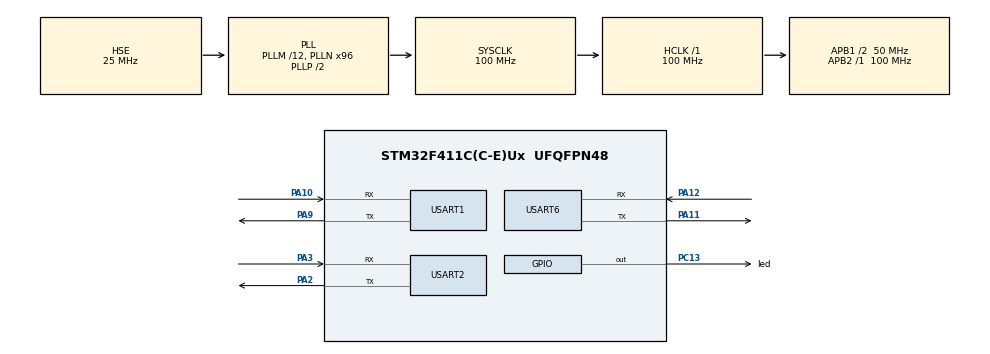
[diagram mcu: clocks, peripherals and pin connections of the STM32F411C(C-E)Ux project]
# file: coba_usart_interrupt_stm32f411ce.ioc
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Dma.Request0=USART2_TX
Dma.USART2_TX.0.Direction=DMA_MEMORY_TO_PERIPH
Dma.USART2_TX.0.FIFOMode=DMA_FIFOMODE_DISABLE
Dma.USART2_TX.0.Instance=DMA1_Stream6
Dma.USART2_TX.0.MemDataAlignment=DMA_MDATAALIGN_BYTE
Dma.USART2_TX.0.MemInc=DMA_MINC_ENABLE
Dma.USART2_TX.0.Mode=DMA_NORMAL
Dma.USART2_TX.0.PeriphDataAlignment=DMA_PDATAALIGN_BYTE
Dma.USART2_TX.0.PeriphInc=DMA_PINC_DISABLE
Dma.USART2_TX.0.Priority=DMA_PRIORITY_LOW
Mcu.Family=STM32F4
Mcu.Name=STM32F411C(C-E)Ux
Mcu.Package=UFQFPN48
NVIC.DMA1_Stream6_IRQn=true\:0\:0\:false\:false\:true\:false\:true
NVIC.PriorityGroup=NVIC_PRIORITYGROUP_4
NVIC.TIM2_IRQn=true\:0\:0\:false\:false\:true\:true\:true
NVIC.USART1_IRQn=true\:0\:0\:false\:false\:true\:true\:true
NVIC.USART2_IRQn=true\:0\:0\:false\:false\:true\:true\:true
NVIC.USART6_IRQn=true\:0\:0\:false\:false\:true\:true\:true
PA10.Mode=Asynchronous
PA10.Signal=USART1_RX
PA11.Mode=Asynchronous
PA11.Signal=USART6_TX
PA12.Mode=Asynchronous
PA12.Signal=USART6_RX
PA13.Mode=Serial_Wire
PA13.Signal=SYS_JTMS-SWDIO
PA14.Mode=Serial_Wire
PA14.Signal=SYS_JTCK-SWCLK
PA2.Mode=Asynchronous
PA2.Signal=USART2_TX
PA3.Mode=Asynchronous
PA3.Signal=USART2_RX
PA9.Mode=Asynchronous
PA9.Signal=USART1_TX
PC13-ANTI_TAMP.GPIO_Label=led
PC13-ANTI_TAMP.Signal=GPIO_Output
PH0\ -\ OSC_IN.Mode=HSE-External-Oscillator
PH0\ -\ OSC_IN.Signal=RCC_OSC_IN
PH1\ -\ OSC_OUT.Mode=HSE-External-Oscillator
PH1\ -\ OSC_OUT.Signal=RCC_OSC_OUT
ProjectManager.HeapSize=0x200
ProjectManager.StackSize=0x400
ProjectManager.TargetToolchain=STM32CubeIDE
RCC.48MHZClocksFreq_Value=50000000
RCC.AHBFreq_Value=100000000
RCC.APB1CLKDivider=RCC_HCLK_DIV2
RCC.APB1Freq_Value=50000000
RCC.APB1TimFreq_Value=100000000
RCC.APB2Freq_Value=100000000
RCC.APB2TimFreq_Value=100000000
RCC.CortexFreq_Value=100000000
RCC.HCLKFreq_Value=100000000
RCC.HSE_VALUE=25000000
RCC.HSI_VALUE=16000000
RCC.LSE_VALUE=32768
RCC.PLLM=12
RCC.PLLN=96
RCC.PLLSourceVirtual=RCC_PLLSOURCE_HSE
RCC.SYSCLKFreq_VALUE=100000000
RCC.SYSCLKSource=RCC_SYSCLKSOURCE_PLLCLK
RCC.VCOOutputFreq_Value=200000000
TIM2.AutoReloadPreload=TIM_AUTORELOAD_PRELOAD_ENABLE
TIM2.Period=65535
TIM2.Prescaler=65535
USART1.VirtualMode=VM_ASYNC
USART2.VirtualMode=VM_ASYNC
USART6.VirtualMode=VM_ASYNC
VP_TIM2_VS_ClockSourceINT.Mode=Internal
board=custom

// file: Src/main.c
/* USER CODE BEGIN Header */
/**
  ******************************************************************************
  * @file           : main.c
  * @brief          : Main program body
  ******************************************************************************
  * @attention
  *
  * Copyright (c) 2022 STMicroelectronics.
  * All rights reserved.
  *
  * This software is licensed under terms that can be found in the LICENSE file
  * in the root directory of this software component.
  * If no LICENSE file comes with this software, it is provided AS-IS.
  *
  ******************************************************************************
  */
/* USER CODE END Header */
#include "main.h"
#include "dma.h"
#include "tim.h"
#include "usart.h"
#include "gpio.h"

/* USER CODE BEGIN Includes */
#include "interrupt.h"
#include "stdio.h"
#include "stdlib.h"
#include "string.h"
/* USER CODE END Includes */

/* USER CODE BEGIN PV */
char data_kirim_usart1[5] = {'i', 't', 's'};
char data_kirim_usart2[11] = {'i', 't', 's'};
char data_kirim_usart6[3] = {'i', 't', 's'};
char data_terima_usart2[4];
char data_terima_usart1[4];
char data_terima_usart6[4];
short int angka_kirim = 0;
/* USER CODE END PV */

void SystemClock_Config(void);

int main(void)
{

  /* MCU Configuration--------------------------------------------------------*/

  /* Reset of all peripherals, Initializes the Flash interface and the Systick. */
  HAL_Init();

  /* Configure the system clock */
  SystemClock_Config();

  /* Initialize all configured peripherals */
  MX_GPIO_Init();
  MX_USART1_UART_Init();
  MX_TIM2_Init();
  MX_DMA_Init();
  MX_USART2_UART_Init();
  MX_USART6_UART_Init();
  /* USER CODE BEGIN 2 */

  // usart using dma
//    HAL_UART_Transmit_DMA(&huart2, (uint8_t*) data_kirim_usart2, strlen(data_kirim_usart2));
//    HAL_UART_Receive_DMA(&huart2, (uint8_t*) data_terima_usart2, strlen(data_terima_usart2));

  // usart using interrupt
  HAL_UART_Receive_IT(&huart6, data_terima_usart6, strlen(data_terima_usart6));
//  HAL_UART_Transmit_IT(&huart6, data_kirim_usart6, strlen(data_kirim_usart6));

  // interrupt
  HAL_TIM_Base_Start_IT(&htim2);
  /* USER CODE END 2 */

  /* Infinite loop */
  while (1)
  {

    /* USER CODE BEGIN 3 */
//	  kirimDataManual();
//	  angka_kirim++;
//	  terimaDataPolling();
//	  kirimDataPolling();

  }
  /* USER CODE END 3 */
}

void SystemClock_Config(void)
{
  RCC_OscInitTypeDef RCC_OscInitStruct = {0};
  RCC_ClkInitTypeDef RCC_ClkInitStruct = {0};

  /** Configure the main internal regulator output voltage
  */
  __HAL_RCC_PWR_CLK_ENABLE();
  __HAL_PWR_VOLTAGESCALING_CONFIG(PWR_REGULATOR_VOLTAGE_SCALE1);
  /** Initializes the RCC Oscillators according to the specified parameters
  * in the RCC_OscInitTypeDef structure.
  */
  RCC_OscInitStruct.OscillatorType = RCC_OSCILLATORTYPE_HSE;
  RCC_OscInitStruct.HSEState = RCC_HSE_ON;
  RCC_OscInitStruct.PLL.PLLState = RCC_PLL_ON;
  RCC_OscInitStruct.PLL.PLLSource = RCC_PLLSOURCE_HSE;
  RCC_OscInitStruct.PLL.PLLM = 12;
  RCC_OscInitStruct.PLL.PLLN = 96;
  RCC_OscInitStruct.PLL.PLLP = RCC_PLLP_DIV2;
  RCC_OscInitStruct.PLL.PLLQ = 4;
  if (HAL_RCC_OscConfig(&RCC_OscInitStruct) != HAL_OK)
  {
    Error_Handler();
  }
  /** Initializes the CPU, AHB and APB buses clocks
  */
  RCC_ClkInitStruct.ClockType = RCC_CLOCKTYPE_HCLK|RCC_CLOCKTYPE_SYSCLK
                              |RCC_CLOCKTYPE_PCLK1|RCC_CLOCKTYPE_PCLK2;
  RCC_ClkInitStruct.SYSCLKSource = RCC_SYSCLKSOURCE_PLLCLK;
  RCC_ClkInitStruct.AHBCLKDivider = RCC_SYSCLK_DIV1;
  RCC_ClkInitStruct.APB1CLKDivider = RCC_HCLK_DIV2;
  RCC_ClkInitStruct.APB2CLKDivider = RCC_HCLK_DIV1;

  if (HAL_RCC_ClockConfig(&RCC_ClkInitStruct, FLASH_LATENCY_3) != HAL_OK)
  {
    Error_Handler();
  }
}

void Error_Handler(void)
{
  __disable_irq();
  while (1)
  {
  }
}
